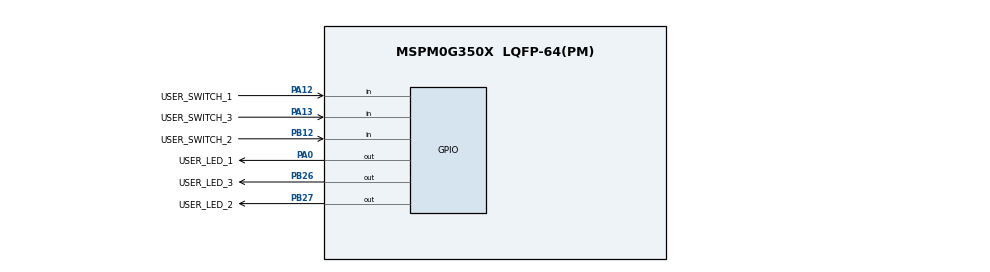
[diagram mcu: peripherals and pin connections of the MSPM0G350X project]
// @cliArgs --device "MSPM0G350X" --package "LQFP-64(PM)" --part "Default"
// @cliArgs --board /ti/boards/LP_MSPM0G3507 --rtos nortos

/**
 * Import the modules used in this configuration.
 */
const GPIO  = scripting.addModule("/ti/driverlib/GPIO", {}, false);
const GPIO1 = GPIO.addInstance();
const GPIO2 = GPIO.addInstance();

/**
 * Write custom configuration values to the imported modules.
 */
GPIO1.$name                         = "GPIO_LEDS";
GPIO1.associatedPins.create(3);
GPIO1.associatedPins[0].$name       = "USER_LED_1";
GPIO1.associatedPins[0].pin.$assign = "PA0";
GPIO1.associatedPins[1].$name       = "USER_LED_2";
GPIO1.associatedPins[1].assignedPin = "27";
GPIO1.associatedPins[1].pin.$assign = "PB27";
GPIO1.associatedPins[2].$name       = "USER_LED_3";
GPIO1.associatedPins[2].initialValue = "SET";
GPIO1.associatedPins[2].pin.$assign = "PB26";

const Board = scripting.addModule("/ti/driverlib/Board", {}, false);

GPIO2.$name                         = "GPIO_SWITCHES";
GPIO2.associatedPins.create(3);
GPIO2.associatedPins[0].$name       = "USER_SWITCH_1";
GPIO2.associatedPins[0].direction   = "INPUT";
GPIO2.associatedPins[0].interruptEn = true;
GPIO2.associatedPins[0].polarity    = "RISE_FALL";
GPIO2.associatedPins[0].pin.$assign = "PA12";
GPIO2.associatedPins[1].$name       = "USER_SWITCH_2";
GPIO2.associatedPins[1].direction   = "INPUT";
GPIO2.associatedPins[1].interruptEn = true;
GPIO2.associatedPins[1].polarity    = "RISE_FALL";
GPIO2.associatedPins[1].pin.$assign = "PB12";
GPIO2.associatedPins[2].$name       = "USER_SWITCH_3";
GPIO2.associatedPins[2].direction   = "INPUT";
GPIO2.associatedPins[2].interruptEn = true;
GPIO2.associatedPins[2].polarity    = "RISE_FALL";
GPIO2.associatedPins[2].pin.$assign = "PA13";

const SYSCTL = scripting.addModule("/ti/driverlib/SYSCTL", {}, false);
SYSCTL.forceDefaultClkConfig = true;
SYSCTL.clockTreeEn  = true;
